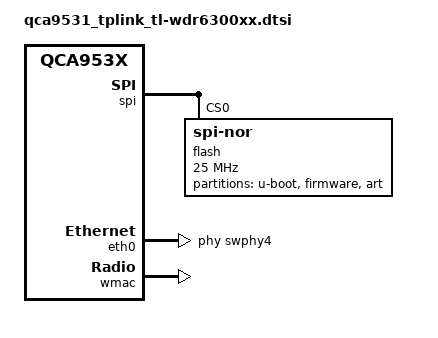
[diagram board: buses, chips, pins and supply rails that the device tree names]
// SPDX-License-Identifier: GPL-2.0-or-later OR MIT

#include <dt-bindings/gpio/gpio.h>
#include <dt-bindings/input/input.h>

#include "qca953x.dtsi"

&spi {
	status = "okay";

	flash@0 {
		compatible = "jedec,spi-nor";
		reg = <0>;
		spi-max-frequency = <25000000>;

		partitions {
			compatible = "fixed-partitions";
			#address-cells = <1>;
			#size-cells = <1>;

			partition@0 {
				label = "u-boot";
				reg = <0x000000 0x020000>;
				read-only;
			};

			partition@20000 {
				compatible = "tplink,firmware";
				label = "firmware";
				reg = <0x020000 0xfd0000>;
			};

			art: partition@ff0000 {
				label = "art";
				reg = <0xff0000 0x010000>;
				read-only;
			};
		};
	};
};

&eth0 {
	status = "okay";

	phy-handle = <&swphy4>;

	mtd-mac-address = <&art 0x0>;
	mtd-mac-address-increment = <1>;
};

&eth1 {
	mtd-mac-address = <&art 0x0>;
};

&wmac {
	status = "okay";

	mtd-cal-data = <&art 0x1000>;
	mtd-mac-address = <&art 0x0>;
};
